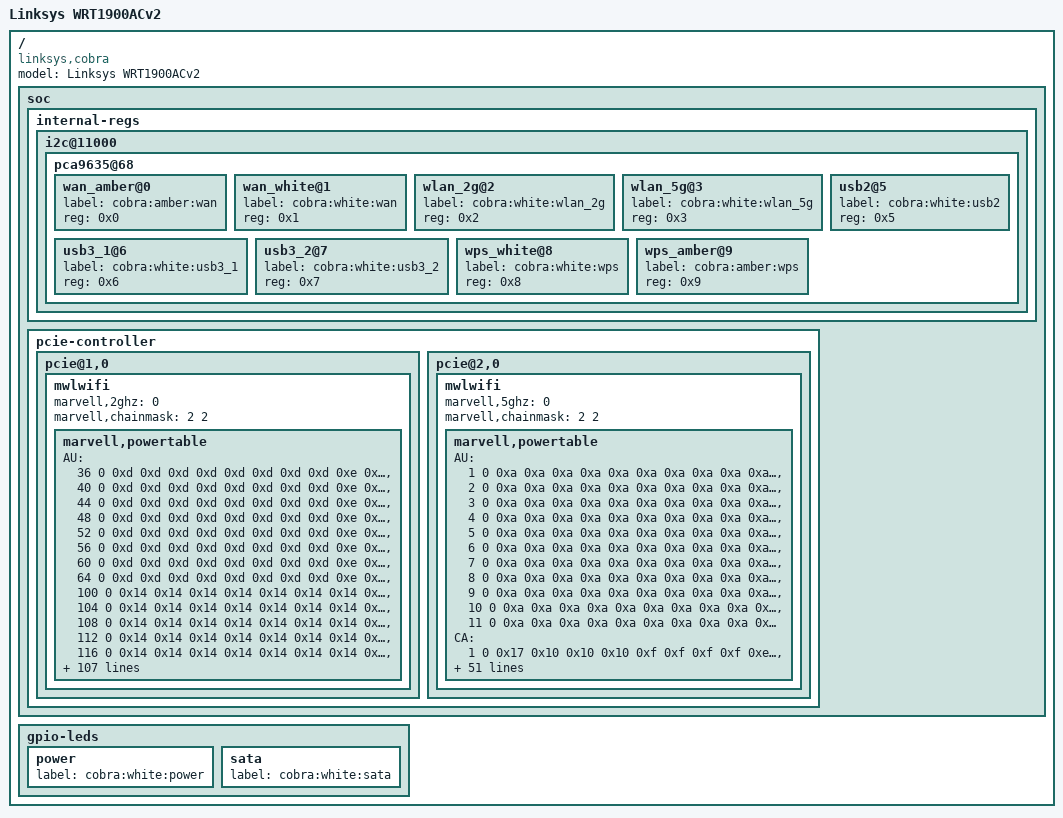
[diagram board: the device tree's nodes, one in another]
/*
 * Device Tree file for the Linksys WRT1900ACv2 (Cobra)
 *
 * Copyright (C) 2015 Imre Kaloz <kaloz@openwrt.org>
 *
 *
 * This file is dual-licensed: you can use it either under the terms
 * of the GPL or the X11 license, at your option. Note that this dual
 * licensing only applies to this file, and not this project as a
 * whole.
 *
 *  a) This file is licensed under the terms of the GNU General Public
 *     License version 2.  This program is licensed "as is" without
 *     any warranty of any kind, whether express or implied.
 *
 * Or, alternatively,
 *
 *  b) Permission is hereby granted, free of charge, to any person
 *     obtaining a copy of this software and associated documentation
 *     files (the "Software"), to deal in the Software without
 *     restriction, including without limitation the rights to use,
 *     copy, modify, merge, publish, distribute, sublicense, and/or
 *     sell copies of the Software, and to permit persons to whom the
 *     Software is furnished to do so, subject to the following
 *     conditions:
 *
 *     The above copyright notice and this permission notice shall be
 *     included in all copies or substantial portions of the Software.
 *
 *     THE SOFTWARE IS PROVIDED "AS IS", WITHOUT WARRANTY OF ANY KIND,
 *     EXPRESS OR IMPLIED, INCLUDING BUT NOT LIMITED TO THE WARRANTIES
 *     OF MERCHANTABILITY, FITNESS FOR A PARTICULAR PURPOSE AND
 *     NONINFRINGEMENT. IN NO EVENT SHALL THE AUTHORS OR COPYRIGHT
 *     HOLDERS BE LIABLE FOR ANY CLAIM, DAMAGES OR OTHER LIABILITY,
 *     WHETHER IN AN ACTION OF CONTRACT, TORT OR OTHERWISE, ARISING
 *     FROM, OUT OF OR IN CONNECTION WITH THE SOFTWARE OR THE USE OR
 *     OTHER DEALINGS IN THE SOFTWARE.
 */

/dts-v1/;
#include "armada-385-linksys.dtsi"

/ {
	model = "Linksys WRT1900ACv2";
	compatible = "linksys,cobra", "linksys,armada385", "marvell,armada385",
		     "marvell,armada380";

	soc {
		internal-regs{
			i2c@11000 {

				pca9635@68 {
				#address-cells = <1>;
				#size-cells = <0>;

					wan_amber@0 {
						label = "cobra:amber:wan";
						reg = <0x0>;
					};

					wan_white@1 {
						label = "cobra:white:wan";
						reg = <0x1>;
					};

					wlan_2g@2 {
						label = "cobra:white:wlan_2g";
						reg = <0x2>;
					};

					wlan_5g@3 {
						label = "cobra:white:wlan_5g";
						reg = <0x3>;
					};

					usb2@5 {
						label = "cobra:white:usb2";
						reg = <0x5>;
					};

					usb3_1@6 {
						label = "cobra:white:usb3_1";
						reg = <0x6>;
					};

					usb3_2@7 {
						label = "cobra:white:usb3_2";
						reg = <0x7>;
					};

					wps_white@8 {
						label = "cobra:white:wps";
						reg = <0x8>;
					};

					wps_amber@9 {
						label = "cobra:amber:wps";
						reg = <0x9>;
					};
				};
			};
		};

		pcie-controller {
			pcie@1,0 {
				mwlwifi {
					marvell,2ghz = <0>;
					marvell,chainmask = <2 2>;
					marvell,powertable {
						AU =
							<36 0 0xd 0xd 0xd 0xd 0xd 0xd 0xd 0xd 0xe 0xe 0xe 0xe 0xe 0xe 0xe 0xe 0 0xf>,
							<40 0 0xd 0xd 0xd 0xd 0xd 0xd 0xd 0xd 0xe 0xe 0xe 0xe 0xe 0xe 0xe 0xe 0 0xf>,
							<44 0 0xd 0xd 0xd 0xd 0xd 0xd 0xd 0xd 0xe 0xe 0xe 0xe 0xe 0xe 0xe 0xe 0 0xf>,
							<48 0 0xd 0xd 0xd 0xd 0xd 0xd 0xd 0xd 0xe 0xe 0xe 0xe 0xe 0xe 0xe 0xe 0 0xf>,
							<52 0 0xd 0xd 0xd 0xd 0xd 0xd 0xd 0xd 0xe 0xe 0xe 0xe 0xe 0xe 0xe 0xe 0 0xf>,
							<56 0 0xd 0xd 0xd 0xd 0xd 0xd 0xd 0xd 0xe 0xe 0xe 0xe 0xe 0xe 0xe 0xe 0 0xf>,
							<60 0 0xd 0xd 0xd 0xd 0xd 0xd 0xd 0xd 0xe 0xe 0xe 0xe 0xe 0xe 0xe 0xe 0 0xf>,
							<64 0 0xd 0xd 0xd 0xd 0xd 0xd 0xd 0xd 0xe 0xe 0xe 0xe 0xe 0xe 0xe 0xe 0 0xf>,
							<100 0 0x14 0x14 0x14 0x14 0x14 0x14 0x14 0x14 0x14 0x14 0x14 0x14 0x14 0x14 0x14 0x14 0 0xf>,
							<104 0 0x14 0x14 0x14 0x14 0x14 0x14 0x14 0x14 0x14 0x14 0x14 0x14 0x14 0x14 0x14 0x14 0 0xf>,
							<108 0 0x14 0x14 0x14 0x14 0x14 0x14 0x14 0x14 0x14 0x14 0x14 0x14 0x14 0x14 0x14 0x14 0 0xf>,
							<112 0 0x14 0x14 0x14 0x14 0x14 0x14 0x14 0x14 0x14 0x14 0x14 0x14 0x14 0x14 0x14 0x14 0 0xf>,
							<116 0 0x14 0x14 0x14 0x14 0x14 0x14 0x14 0x14 0x14 0x14 0x14 0x14 0x14 0x14 0x14 0x14 0 0xf>,
							<120 0 0x14 0x14 0x14 0x14 0x14 0x14 0x14 0x14 0x14 0x14 0x14 0x14 0x14 0x14 0x14 0x14 0 0xf>,
							<124 0 0x14 0x14 0x14 0x14 0x14 0x14 0x14 0x14 0x14 0x14 0x14 0x14 0x14 0x14 0x14 0x14 0 0xf>,
							<128 0 0x14 0x14 0x14 0x14 0x14 0x14 0x14 0x14 0x14 0x14 0x14 0x14 0x14 0x14 0x14 0x14 0 0xf>,
							<132 0 0x14 0x14 0x14 0x14 0x14 0x14 0x14 0x14 0x14 0x14 0x14 0x14 0x14 0x14 0x14 0x14 0 0xf>,
							<136 0 0x14 0x14 0x14 0x14 0x14 0x14 0x14 0x14 0x14 0x14 0x14 0x14 0x14 0x14 0x14 0x14 0 0xf>,
							<140 0 0x14 0x14 0x14 0x14 0x14 0x14 0x14 0x14 0x14 0x14 0x14 0x14 0x14 0x14 0x14 0x14 0 0xf>,
							<149 0 0x19 0x19 0x19 0x17 0x19 0x19 0x16 0x15 0x19 0x19 0x16 0x15 0x19 0x19 0x16 0x15 0 0xf>,
							<153 0 0x19 0x19 0x19 0x17 0x19 0x19 0x16 0x15 0x19 0x19 0x16 0x15 0x19 0x19 0x16 0x15 0 0xf>,
							<157 0 0x19 0x19 0x19 0x17 0x19 0x19 0x16 0x15 0x19 0x19 0x16 0x15 0x19 0x19 0x16 0x15 0 0xf>,
							<161 0 0x19 0x19 0x19 0x17 0x19 0x19 0x16 0x15 0x19 0x19 0x16 0x15 0x19 0x19 0x16 0x15 0 0xf>,
							<165 0 0x19 0x19 0x19 0x17 0x19 0x19 0x16 0x15 0x19 0x19 0x16 0x15 0x19 0x19 0x16 0x15 0 0xf>;
						CA =
							<36 0 0x9 0x9 0x9 0x9 0x9 0x9 0x9 0x9 0x9 0x9 0x9 0x9 0x9 0x9 0x9 0x9 0 0xf>,
							<40 0 0x9 0x9 0x9 0x9 0x9 0x9 0x9 0x9 0x9 0x9 0x9 0x9 0x9 0x9 0x9 0x9 0 0xf>,
							<44 0 0x9 0x9 0x9 0x9 0x9 0x9 0x9 0x9 0x9 0x9 0x9 0x9 0x9 0x9 0x9 0x9 0 0xf>,
							<48 0 0x9 0x9 0x9 0x9 0x9 0x9 0x9 0x9 0x9 0x9 0x9 0x9 0x9 0x9 0x9 0x9 0 0xf>,
							<52 0 0x11 0x11 0x11 0x11 0x10 0x10 0x10 0x10 0x12 0x12 0x12 0x12 0x10 0x10 0x10 0x10 0 0xf>,
							<56 0 0x11 0x11 0x11 0x11 0x10 0x10 0x10 0x10 0x12 0x12 0x12 0x12 0x10 0x10 0x10 0x10 0 0xf>,
							<60 0 0x11 0x11 0x11 0x11 0x10 0x10 0x10 0x10 0x12 0x12 0x12 0x12 0x10 0x10 0x10 0x10 0 0xf>,
							<64 0 0x11 0x11 0x11 0x11 0x10 0x10 0x10 0x10 0x12 0x12 0x12 0x12 0x10 0x10 0x10 0x10 0 0xf>,
							<100 0 0x10 0x10 0x10 0x10 0x11 0x11 0x11 0x11 0x12 0x12 0x12 0x12 0x10 0x10 0x10 0x10 0 0xf>,
							<104 0 0x11 0x11 0x11 0x11 0x10 0x10 0x10 0x10 0x12 0x12 0x12 0x12 0x10 0x10 0x10 0x10 0 0xf>,
							<108 0 0x11 0x11 0x11 0x11 0x10 0x10 0x10 0x10 0x11 0x11 0x11 0x11 0x10 0x10 0x10 0x10 0 0xf>,
							<112 0 0x11 0x11 0x11 0x11 0x10 0x10 0x10 0x10 0x11 0x11 0x11 0x11 0x10 0x10 0x10 0x10 0 0xf>,
							<116 0 0x11 0x11 0x11 0x11 0x10 0x10 0x10 0x10 0x11 0x11 0x11 0x11 0x10 0x10 0x10 0x10 0 0xf>,
							<120 0 0x11 0x11 0x11 0x11 0x10 0x10 0x10 0x10 0x11 0x11 0x11 0x11 0x10 0x10 0x10 0x10 0 0xf>,
							<124 0 0x11 0x11 0x11 0x11 0x10 0x10 0x10 0x10 0x11 0x11 0x11 0x11 0x10 0x10 0x10 0x10 0 0xf>,
							<128 0 0x11 0x11 0x11 0x11 0x10 0x10 0x10 0x10 0x11 0x11 0x11 0x11 0x10 0x10 0x10 0x10 0 0xf>,
							<132 0 0x11 0x11 0x11 0x11 0x10 0x10 0x10 0x10 0x11 0x11 0x11 0x11 0x10 0x10 0x10 0x10 0 0xf>,
							<136 0 0x11 0x11 0x11 0x11 0x10 0x10 0x10 0x10 0x11 0x11 0x11 0x11 0x10 0x10 0x10 0x10 0 0xf>,
							<140 0 0x11 0x11 0x11 0x11 0x10 0x10 0x10 0x10 0x11 0x11 0x11 0x11 0x10 0x10 0x10 0x10 0 0xf>,
							<149 0 0x16 0x16 0x16 0x16 0x16 0x16 0x16 0x16 0x15 0x15 0x15 0x15 0x15 0x15 0x15 0x15 0 0xf>,
							<153 0 0x16 0x16 0x16 0x16 0x15 0x15 0x15 0x15 0x15 0x15 0x15 0x15 0x15 0x15 0x15 0x15 0 0xf>,
							<157 0 0x16 0x16 0x16 0x16 0x15 0x15 0x15 0x15 0x15 0x15 0x15 0x15 0x15 0x15 0x15 0x15 0 0xf>,
							<161 0 0x16 0x16 0x16 0x16 0x15 0x15 0x15 0x15 0x15 0x15 0x15 0x15 0x15 0x15 0x15 0x15 0 0xf>,
							<165 0 0x15 0x15 0x15 0x15 0x15 0x15 0x15 0x15 0x15 0x15 0x15 0x15 0x15 0x15 0x15 0x15 0 0xf>;
						CN =
							<36 0 0xd 0xd 0xd 0xd 0xd 0xd 0xd 0xd 0xe 0xe 0xe 0xe 0xe 0xe 0xe 0xe 0 0xf>,
							<40 0 0xd 0xd 0xd 0xd 0xd 0xd 0xd 0xd 0xe 0xe 0xe 0xe 0xe 0xe 0xe 0xe 0 0xf>,
							<44 0 0xd 0xd 0xd 0xd 0xd 0xd 0xd 0xd 0xe 0xe 0xe 0xe 0xe 0xe 0xe 0xe 0 0xf>,
							<48 0 0xd 0xd 0xd 0xd 0xd 0xd 0xd 0xd 0xe 0xe 0xe 0xe 0xe 0xe 0xe 0xe 0 0xf>,
							<52 0 0xd 0xd 0xd 0xd 0xd 0xd 0xd 0xd 0xe 0xe 0xe 0xe 0xe 0xe 0xe 0xe 0 0xf>,
							<56 0 0xd 0xd 0xd 0xd 0xd 0xd 0xd 0xd 0xe 0xe 0xe 0xe 0xe 0xe 0xe 0xe 0 0xf>,
							<60 0 0xd 0xd 0xd 0xd 0xd 0xd 0xd 0xd 0xe 0xe 0xe 0xe 0xe 0xe 0xe 0xe 0 0xf>,
							<64 0 0xd 0xd 0xd 0xd 0xd 0xd 0xd 0xd 0xe 0xe 0xe 0xe 0xe 0xe 0xe 0xe 0 0xf>,
							<100 0 0xd 0xd 0xd 0xd 0xd 0xd 0xd 0xd 0xe 0xe 0xe 0xe 0xe 0xe 0xe 0xe 0 0xf>,
							<104 0 0xd 0xd 0xd 0xd 0xd 0xd 0xd 0xd 0xe 0xe 0xe 0xe 0xe 0xe 0xe 0xe 0 0xf>,
							<108 0 0xd 0xd 0xd 0xd 0xd 0xd 0xd 0xd 0xe 0xe 0xe 0xe 0xe 0xe 0xe 0xe 0 0xf>,
							<112 0 0xd 0xd 0xd 0xd 0xd 0xd 0xd 0xd 0xe 0xe 0xe 0xe 0xe 0xe 0xe 0xe 0 0xf>,
							<116 0 0xd 0xd 0xd 0xd 0xd 0xd 0xd 0xd 0xe 0xe 0xe 0xe 0xe 0xe 0xe 0xe 0 0xf>,
							<120 0 0xd 0xd 0xd 0xd 0xd 0xd 0xd 0xd 0xe 0xe 0xe 0xe 0xe 0xe 0xe 0xe 0 0xf>,
							<124 0 0xd 0xd 0xd 0xd 0xd 0xd 0xd 0xd 0xe 0xe 0xe 0xe 0xe 0xe 0xe 0xe 0 0xf>,
							<128 0 0xd 0xd 0xd 0xd 0xd 0xd 0xd 0xd 0xe 0xe 0xe 0xe 0xe 0xe 0xe 0xe 0 0xf>,
							<132 0 0xd 0xd 0xd 0xd 0xd 0xd 0xd 0xd 0xe 0xe 0xe 0xe 0xe 0xe 0xe 0xe 0 0xf>,
							<136 0 0xd 0xd 0xd 0xd 0xd 0xd 0xd 0xd 0xe 0xe 0xe 0xe 0xe 0xe 0xe 0xe 0 0xf>,
							<140 0 0xd 0xd 0xd 0xd 0xd 0xd 0xd 0xd 0xe 0xe 0xe 0xe 0xe 0xe 0xe 0xe 0 0xf>,
							<149 0 0x14 0x14 0x14 0x14 0x13 0x13 0x13 0x13 0x11 0x11 0x11 0x11 0x10 0x10 0x10 0x10 0 0xf>,
							<153 0 0x16 0x16 0x16 0x16 0x15 0x15 0x15 0x15 0x14 0x14 0x14 0x14 0x10 0x10 0x10 0x10 0 0xf>,
							<157 0 0x16 0x16 0x16 0x16 0x15 0x15 0x15 0x15 0x14 0x14 0x14 0x14 0x10 0x10 0x10 0x10 0 0xf>,
							<161 0 0x16 0x16 0x16 0x16 0x15 0x15 0x15 0x15 0x14 0x14 0x14 0x14 0x10 0x10 0x10 0x10 0 0xf>,
							<165 0 0x13 0x13 0x13 0x13 0x13 0x13 0x13 0x13 0x14 0x14 0x14 0x14 0x10 0x10 0x10 0x10 0 0xf>;
						ETSI =
							<36 0 0xd 0xd 0xd 0xd 0xd 0xd 0xd 0xd 0xe 0xe 0xe 0xe 0xe 0xe 0xe 0xe 0 0xf>,
							<40 0 0xd 0xd 0xd 0xd 0xd 0xd 0xd 0xd 0xe 0xe 0xe 0xe 0xe 0xe 0xe 0xe 0 0xf>,
							<44 0 0xd 0xd 0xd 0xd 0xd 0xd 0xd 0xd 0xe 0xe 0xe 0xe 0xe 0xe 0xe 0xe 0 0xf>,
							<48 0 0xd 0xd 0xd 0xd 0xd 0xd 0xd 0xd 0xe 0xe 0xe 0xe 0xe 0xe 0xe 0xe 0 0xf>,
							<52 0 0xd 0xd 0xd 0xd 0xd 0xd 0xd 0xd 0xe 0xe 0xe 0xe 0xe 0xe 0xe 0xe 0 0xf>,
							<56 0 0xd 0xd 0xd 0xd 0xd 0xd 0xd 0xd 0xe 0xe 0xe 0xe 0xe 0xe 0xe 0xe 0 0xf>,
							<60 0 0xd 0xd 0xd 0xd 0xd 0xd 0xd 0xd 0xe 0xe 0xe 0xe 0xe 0xe 0xe 0xe 0 0xf>,
							<64 0 0xd 0xd 0xd 0xd 0xd 0xd 0xd 0xd 0xe 0xe 0xe 0xe 0xe 0xe 0xe 0xe 0 0xf>,
							<100 0 0xd 0xd 0xd 0xd 0xd 0xd 0xd 0xd 0xe 0xe 0xe 0xe 0xe 0xe 0xe 0xe 0 0xf>,
							<104 0 0xd 0xd 0xd 0xd 0xd 0xd 0xd 0xd 0xe 0xe 0xe 0xe 0xe 0xe 0xe 0xe 0 0xf>,
							<108 0 0xd 0xd 0xd 0xd 0xd 0xd 0xd 0xd 0xe 0xe 0xe 0xe 0xe 0xe 0xe 0xe 0 0xf>,
							<112 0 0xd 0xd 0xd 0xd 0xd 0xd 0xd 0xd 0xe 0xe 0xe 0xe 0xe 0xe 0xe 0xe 0 0xf>,
							<116 0 0xd 0xd 0xd 0xd 0xd 0xd 0xd 0xd 0xe 0xe 0xe 0xe 0xe 0xe 0xe 0xe 0 0xf>,
							<120 0 0xd 0xd 0xd 0xd 0xd 0xd 0xd 0xd 0xe 0xe 0xe 0xe 0xe 0xe 0xe 0xe 0 0xf>,
							<124 0 0xd 0xd 0xd 0xd 0xd 0xd 0xd 0xd 0xe 0xe 0xe 0xe 0xe 0xe 0xe 0xe 0 0xf>,
							<128 0 0xd 0xd 0xd 0xd 0xd 0xd 0xd 0xd 0xe 0xe 0xe 0xe 0xe 0xe 0xe 0xe 0 0xf>,
							<132 0 0xd 0xd 0xd 0xd 0xd 0xd 0xd 0xd 0xe 0xe 0xe 0xe 0xe 0xe 0xe 0xe 0 0xf>,
							<136 0 0xd 0xd 0xd 0xd 0xd 0xd 0xd 0xd 0xe 0xe 0xe 0xe 0xe 0xe 0xe 0xe 0 0xf>,
							<140 0 0xd 0xd 0xd 0xd 0xd 0xd 0xd 0xd 0xe 0xe 0xe 0xe 0xe 0xe 0xe 0xe 0 0xf>,
							<149 0 0xd 0xd 0xd 0xd 0xd 0xd 0xd 0xd 0xe 0xe 0xe 0xe 0xe 0xe 0xe 0xe 0 0xf>;
						FCC =
							<36 0 0x12 0x12 0x12 0x12 0x12 0x12 0x12 0x12 0x10 0x10 0x10 0x10 0xf 0xf 0xf 0xf 0 0xf>,
							<40 0 0x16 0x16 0x16 0x16 0x16 0x16 0x16 0x16 0x16 0x16 0x16 0x16 0xf 0xf 0xf 0xf 0 0xf>,
							<44 0 0x16 0x16 0x16 0x16 0x16 0x16 0x16 0x16 0x16 0x16 0x16 0x16 0xf 0xf 0xf 0xf 0 0xf>,
							<48 0 0x16 0x16 0x16 0x16 0x16 0x16 0x16 0x16 0x16 0x16 0x16 0x16 0xf 0xf 0xf 0xf 0 0xf>,
							<52 0 0x11 0x11 0x11 0x11 0x10 0x10 0x10 0x10 0x12 0x12 0x12 0x12 0x10 0x10 0x10 0x10 0 0xf>,
							<56 0 0x11 0x11 0x11 0x11 0x10 0x10 0x10 0x10 0x12 0x12 0x12 0x12 0x10 0x10 0x10 0x10 0 0xf>,
							<60 0 0x11 0x11 0x11 0x11 0x10 0x10 0x10 0x10 0x12 0x12 0x12 0x12 0x10 0x10 0x10 0x10 0 0xf>,
							<64 0 0x11 0x11 0x11 0x11 0x10 0x10 0x10 0x10 0x12 0x12 0x12 0x12 0x10 0x10 0x10 0x10 0 0xf>,
							<100 0 0x10 0x10 0x10 0x10 0x11 0x11 0x11 0x11 0x12 0x12 0x12 0x12 0x10 0x10 0x10 0x10 0 0xf>,
							<104 0 0x11 0x11 0x11 0x11 0x10 0x10 0x10 0x10 0x12 0x12 0x12 0x12 0x10 0x10 0x10 0x10 0 0xf>,
							<108 0 0x11 0x11 0x11 0x11 0x10 0x10 0x10 0x10 0x11 0x11 0x11 0x11 0x10 0x10 0x10 0x10 0 0xf>,
							<112 0 0x11 0x11 0x11 0x11 0x10 0x10 0x10 0x10 0x11 0x11 0x11 0x11 0x10 0x10 0x10 0x10 0 0xf>,
							<116 0 0x11 0x11 0x11 0x11 0x10 0x10 0x10 0x10 0x11 0x11 0x11 0x11 0x10 0x10 0x10 0x10 0 0xf>,
							<120 0 0x11 0x11 0x11 0x11 0x10 0x10 0x10 0x10 0x11 0x11 0x11 0x11 0x10 0x10 0x10 0x10 0 0xf>,
							<124 0 0x11 0x11 0x11 0x11 0x10 0x10 0x10 0x10 0x11 0x11 0x11 0x11 0x10 0x10 0x10 0x10 0 0xf>,
							<128 0 0x11 0x11 0x11 0x11 0x10 0x10 0x10 0x10 0x11 0x11 0x11 0x11 0x10 0x10 0x10 0x10 0 0xf>,
							<132 0 0x11 0x11 0x11 0x11 0x10 0x10 0x10 0x10 0x11 0x11 0x11 0x11 0x10 0x10 0x10 0x10 0 0xf>,
							<136 0 0x11 0x11 0x11 0x11 0x10 0x10 0x10 0x10 0x11 0x11 0x11 0x11 0x10 0x10 0x10 0x10 0 0xf>,
							<140 0 0x11 0x11 0x11 0x11 0x10 0x10 0x10 0x10 0x11 0x11 0x11 0x11 0x10 0x10 0x10 0x10 0 0xf>,
							<149 0 0x16 0x16 0x16 0x16 0x16 0x16 0x16 0x16 0x15 0x15 0x15 0x15 0x15 0x15 0x15 0x15 0 0xf>,
							<153 0 0x16 0x16 0x16 0x16 0x15 0x15 0x15 0x15 0x15 0x15 0x15 0x15 0x15 0x15 0x15 0x15 0 0xf>,
							<157 0 0x16 0x16 0x16 0x16 0x15 0x15 0x15 0x15 0x15 0x15 0x15 0x15 0x15 0x15 0x15 0x15 0 0xf>,
							<161 0 0x16 0x16 0x16 0x16 0x15 0x15 0x15 0x15 0x15 0x15 0x15 0x15 0x15 0x15 0x15 0x15 0 0xf>,
							<165 0 0x15 0x15 0x15 0x15 0x15 0x15 0x15 0x15 0x15 0x15 0x15 0x15 0x15 0x15 0x15 0x15 0 0xf>;
					};
				};
			};

			pcie@2,0 {
				mwlwifi {
					marvell,5ghz = <0>;
					marvell,chainmask = <2 2>;
					marvell,powertable {
						AU =
							<1 0 0xa 0xa 0xa 0xa 0xa 0xa 0xa 0xa 0xa 0xa 0xa 0xa 0x0 0x0 0x0 0x0 0 0xf>,
							<2 0 0xa 0xa 0xa 0xa 0xa 0xa 0xa 0xa 0xa 0xa 0xa 0xa 0x0 0x0 0x0 0x0 0 0xf>,
							<3 0 0xa 0xa 0xa 0xa 0xa 0xa 0xa 0xa 0xa 0xa 0xa 0xa 0x0 0x0 0x0 0x0 0 0xf>,
							<4 0 0xa 0xa 0xa 0xa 0xa 0xa 0xa 0xa 0xa 0xa 0xa 0xa 0x0 0x0 0x0 0x0 0 0xf>,
							<5 0 0xa 0xa 0xa 0xa 0xa 0xa 0xa 0xa 0xa 0xa 0xa 0xa 0x0 0x0 0x0 0x0 0 0xf>,
							<6 0 0xa 0xa 0xa 0xa 0xa 0xa 0xa 0xa 0xa 0xa 0xa 0xa 0x0 0x0 0x0 0x0 0 0xf>,
							<7 0 0xa 0xa 0xa 0xa 0xa 0xa 0xa 0xa 0xa 0xa 0xa 0xa 0x0 0x0 0x0 0x0 0 0xf>,
							<8 0 0xa 0xa 0xa 0xa 0xa 0xa 0xa 0xa 0xa 0xa 0xa 0xa 0x0 0x0 0x0 0x0 0 0xf>,
							<9 0 0xa 0xa 0xa 0xa 0xa 0xa 0xa 0xa 0xa 0xa 0xa 0xa 0x0 0x0 0x0 0x0 0 0xf>,
							<10 0 0xa 0xa 0xa 0xa 0xa 0xa 0xa 0xa 0xa 0xa 0xa 0xa 0x0 0x0 0x0 0x0 0 0xf>,
							<11 0 0xa 0xa 0xa 0xa 0xa 0xa 0xa 0xa 0xa 0xa 0xa 0xa 0x0 0x0 0x0 0x0 0 0xf>;
						CA =
							<1 0 0x17 0x10 0x10 0x10 0xf 0xf 0xf 0xf 0xe 0xe 0xe 0xe 0x0 0x0 0x0 0x0 0 0xf>,
							<2 0 0x18 0x16 0x16 0x16 0x16 0x16 0x16 0x14 0x11 0x11 0x11 0x11 0x0 0x0 0x0 0x0 0 0xf>,
							<3 0 0x18 0x16 0x16 0x16 0x16 0x16 0x16 0x14 0x11 0x11 0x11 0x11 0x0 0x0 0x0 0x0 0 0xf>,
							<4 0 0x18 0x16 0x16 0x16 0x16 0x16 0x16 0x14 0x11 0x11 0x11 0x11 0x0 0x0 0x0 0x0 0 0xf>,
							<5 0 0x18 0x16 0x16 0x16 0x16 0x16 0x16 0x14 0x11 0x11 0x11 0x11 0x0 0x0 0x0 0x0 0 0xf>,
							<6 0 0x18 0x16 0x16 0x16 0x16 0x16 0x16 0x14 0x11 0x11 0x11 0x11 0x0 0x0 0x0 0x0 0 0xf>,
							<7 0 0x18 0x16 0x16 0x16 0x16 0x16 0x16 0x14 0x11 0x11 0x11 0x11 0x0 0x0 0x0 0x0 0 0xf>,
							<8 0 0x18 0x16 0x16 0x16 0x16 0x16 0x16 0x14 0x11 0x11 0x11 0x11 0x0 0x0 0x0 0x0 0 0xf>,
							<9 0 0x18 0x16 0x16 0x16 0x16 0x16 0x16 0x14 0x11 0x11 0x11 0x11 0x0 0x0 0x0 0x0 0 0xf>,
							<10 0 0x18 0x16 0x16 0x16 0x16 0x16 0x16 0x14 0x11 0x11 0x11 0x11 0x0 0x0 0x0 0x0 0 0xf>,
							<11 0 0x17 0x12 0x12 0x12 0x13 0x13 0x13 0x13 0xf 0xf 0xf 0xf 0x0 0x0 0x0 0x0 0 0xf>;
						CN =
							<1 0 0xa 0xa 0xa 0xa 0xa 0xa 0xa 0xa 0xa 0xa 0xa 0xa 0x0 0x0 0x0 0x0 0 0xf>,
							<2 0 0xa 0xa 0xa 0xa 0xa 0xa 0xa 0xa 0xa 0xa 0xa 0xa 0x0 0x0 0x0 0x0 0 0xf>,
							<3 0 0xa 0xa 0xa 0xa 0xa 0xa 0xa 0xa 0xa 0xa 0xa 0xa 0x0 0x0 0x0 0x0 0 0xf>,
							<4 0 0xa 0xa 0xa 0xa 0xa 0xa 0xa 0xa 0xa 0xa 0xa 0xa 0x0 0x0 0x0 0x0 0 0xf>,
							<5 0 0xa 0xa 0xa 0xa 0xa 0xa 0xa 0xa 0xa 0xa 0xa 0xa 0x0 0x0 0x0 0x0 0 0xf>,
							<6 0 0xa 0xa 0xa 0xa 0xa 0xa 0xa 0xa 0xa 0xa 0xa 0xa 0x0 0x0 0x0 0x0 0 0xf>,
							<7 0 0xa 0xa 0xa 0xa 0xa 0xa 0xa 0xa 0xa 0xa 0xa 0xa 0x0 0x0 0x0 0x0 0 0xf>,
							<8 0 0xa 0xa 0xa 0xa 0xa 0xa 0xa 0xa 0xa 0xa 0xa 0xa 0x0 0x0 0x0 0x0 0 0xf>,
							<9 0 0xa 0xa 0xa 0xa 0xa 0xa 0xa 0xa 0xa 0xa 0xa 0xa 0x0 0x0 0x0 0x0 0 0xf>,
							<10 0 0xa 0xa 0xa 0xa 0xa 0xa 0xa 0xa 0xa 0xa 0xa 0xa 0x0 0x0 0x0 0x0 0 0xf>,
							<11 0 0xa 0xa 0xa 0xa 0xa 0xa 0xa 0xa 0xa 0xa 0xa 0xa 0x0 0x0 0x0 0x0 0 0xf>,
							<12 0 0xa 0xa 0xa 0xa 0xa 0xa 0xa 0xa 0xa 0xa 0xa 0xa 0x0 0x0 0x0 0x0 0 0xf>,
							<13 0 0xa 0xa 0xa 0xa 0xa 0xa 0xa 0xa 0xa 0xa 0xa 0xa 0x0 0x0 0x0 0x0 0 0xf>,
							<14 0 0xa 0xa 0xa 0xa 0xa 0xa 0xa 0xa 0xa 0xa 0xa 0xa 0x0 0x0 0x0 0x0 0 0xf>;
						ETSI =
							<1 0 0xa 0xa 0xa 0xa 0xa 0xa 0xa 0xa 0xa 0xa 0xa 0xa 0x0 0x0 0x0 0x0 0 0xf>,
							<2 0 0xa 0xa 0xa 0xa 0xa 0xa 0xa 0xa 0xa 0xa 0xa 0xa 0x0 0x0 0x0 0x0 0 0xf>,
							<3 0 0xa 0xa 0xa 0xa 0xa 0xa 0xa 0xa 0xa 0xa 0xa 0xa 0x0 0x0 0x0 0x0 0 0xf>,
							<4 0 0xa 0xa 0xa 0xa 0xa 0xa 0xa 0xa 0xa 0xa 0xa 0xa 0x0 0x0 0x0 0x0 0 0xf>,
							<5 0 0xa 0xa 0xa 0xa 0xa 0xa 0xa 0xa 0xa 0xa 0xa 0xa 0x0 0x0 0x0 0x0 0 0xf>,
							<6 0 0xa 0xa 0xa 0xa 0xa 0xa 0xa 0xa 0xa 0xa 0xa 0xa 0x0 0x0 0x0 0x0 0 0xf>,
							<7 0 0xa 0xa 0xa 0xa 0xa 0xa 0xa 0xa 0xa 0xa 0xa 0xa 0x0 0x0 0x0 0x0 0 0xf>,
							<8 0 0xa 0xa 0xa 0xa 0xa 0xa 0xa 0xa 0xa 0xa 0xa 0xa 0x0 0x0 0x0 0x0 0 0xf>,
							<9 0 0xa 0xa 0xa 0xa 0xa 0xa 0xa 0xa 0xa 0xa 0xa 0xa 0x0 0x0 0x0 0x0 0 0xf>,
							<10 0 0xa 0xa 0xa 0xa 0xa 0xa 0xa 0xa 0xa 0xa 0xa 0xa 0x0 0x0 0x0 0x0 0 0xf>,
							<11 0 0xa 0xa 0xa 0xa 0xa 0xa 0xa 0xa 0xa 0xa 0xa 0xa 0x0 0x0 0x0 0x0 0 0xf>,
							<12 0 0xa 0xa 0xa 0xa 0xa 0xa 0xa 0xa 0xa 0xa 0xa 0xa 0x0 0x0 0x0 0x0 0 0xf>,
							<13 0 0xa 0xa 0xa 0xa 0xa 0xa 0xa 0xa 0xa 0xa 0xa 0xa 0x0 0x0 0x0 0x0 0 0xf>;
						FCC =
							<1 0 0x17 0x10 0x10 0x10 0xf 0xf 0xf 0xf 0xe 0xe 0xe 0xe 0x0 0x0 0x0 0x0 0 0xf>,
							<2 0 0x18 0x16 0x16 0x16 0x16 0x16 0x16 0x14 0x11 0x11 0x11 0x11 0x0 0x0 0x0 0x0 0 0xf>,
							<3 0 0x18 0x16 0x16 0x16 0x16 0x16 0x16 0x14 0x11 0x11 0x11 0x11 0x0 0x0 0x0 0x0 0 0xf>,
							<4 0 0x18 0x16 0x16 0x16 0x16 0x16 0x16 0x14 0x11 0x11 0x11 0x11 0x0 0x0 0x0 0x0 0 0xf>,
							<5 0 0x18 0x16 0x16 0x16 0x16 0x16 0x16 0x14 0x11 0x11 0x11 0x11 0x0 0x0 0x0 0x0 0 0xf>,
							<6 0 0x18 0x16 0x16 0x16 0x16 0x16 0x16 0x14 0x11 0x11 0x11 0x11 0x0 0x0 0x0 0x0 0 0xf>,
							<7 0 0x18 0x16 0x16 0x16 0x16 0x16 0x16 0x14 0x11 0x11 0x11 0x11 0x0 0x0 0x0 0x0 0 0xf>,
							<8 0 0x18 0x16 0x16 0x16 0x16 0x16 0x16 0x14 0x11 0x11 0x11 0x11 0x0 0x0 0x0 0x0 0 0xf>,
							<9 0 0x18 0x16 0x16 0x16 0x16 0x16 0x16 0x14 0x11 0x11 0x11 0x11 0x0 0x0 0x0 0x0 0 0xf>,
							<10 0 0x18 0x16 0x16 0x16 0x16 0x16 0x16 0x14 0x11 0x11 0x11 0x11 0x0 0x0 0x0 0x0 0 0xf>,
							<11 0 0x17 0x12 0x12 0x12 0x13 0x13 0x13 0x13 0xf 0xf 0xf 0xf 0x0 0x0 0x0 0x0 0 0xf>;
					};
				};
			};
		};
	};

	gpio-leds {
		power {
			label = "cobra:white:power";
		};

		sata {
			label = "cobra:white:sata";
		};
	};
};
